VERSION ""

NS_ :

BS_:

BU_: TesterTool ECU0

BO_ 849 IPDUM_Mul0Tx: 8 ECU0
 SG_ IpduM_MulMsg0Tx_Sig10_Static : 56|8@1+ (1,0) [0|255] ""  TesterTool
 SG_ IpduM_MulMsg0Tx_Sig9_Static : 48|8@1+ (1,0) [0|255] ""  TesterTool
 SG_ IpduM_MulMsg0Tx_Sig8_Static : 40|8@1+ (1,0) [0|255] ""  TesterTool
 SG_ IpduM_MulMsg0Tx_Sig7_Static : 32|8@1+ (1,0) [0|255] ""  TesterTool
 SG_ IpduM_MulMsg0Tx_Sig6_Static : 24|8@1+ (1,0) [0|255] ""  TesterTool
 SG_ IpduM_MulMsg0Tx_Sig5_Static : 16|8@1+ (1,0) [0|255] ""  TesterTool
 SG_ IpduM_MulMsg0Tx_Sig4_Dyn m1 : 14|2@1+ (1,0) [0|3] ""  TesterTool
 SG_ IpduM_MulMsg0Tx_Sig3_Dyn m1 : 8|6@1+ (1,0) [0|63] ""  TesterTool
 SG_ IpduM_MulMsg0Tx_Sig2_Dyn m0 : 11|5@1+ (1,0) [0|31] ""  TesterTool
 SG_ IpduM_MulMsg0Tx_Sig1_Dyn m0 : 8|3@1+ (1,0) [0|7] ""  TesterTool
 SG_ IpduM_MulMsg0Tx_Sig0_Selector M : 6|2@1+ (1,0) [0|3] ""  TesterTool

BO_ 768 IPDUM_Mul0Rx: 8 TesterTool
 SG_ IpduM_MulMsg0Rx_Sig9_Static : 56|8@1+ (1,0) [0|255] ""  ECU0
 SG_ IpduM_MulMsg0Rx_Sig8_Static : 48|8@1+ (1,0) [0|255] ""  ECU0
 SG_ IpduM_MulMsg0Rx_Sig7_Static : 40|8@1+ (1,0) [0|255] ""  ECU0
 SG_ IpduM_MulMsg0Rx_Sig6_Static : 32|8@1+ (1,0) [0|255] ""  ECU0
 SG_ IpduM_MulMsg0Rx_Sig5_Static : 24|8@1+ (1,0) [0|255] ""  ECU0
 SG_ IpduM_MulMsg0Rx_Sig4_Static : 16|8@1+ (1,0) [0|255] ""  ECU0
 SG_ IpduM_MulMsg0Rx_Sig3_Dyn m1 : 12|4@1+ (1,0) [0|15] ""  ECU0
 SG_ IpduM_MulMsg0Rx_Sig2_Dyn m1 : 8|4@1+ (1,0) [0|15] ""  ECU0
 SG_ IpduM_MulMsg0Rx_Sig1_Dyn m0 : 8|8@1+ (1,0) [0|255] ""  ECU0
 SG_ IpduM_MulMsg0Rx_Sig0_Seclector M : 6|2@1+ (1,0) [0|3] ""  ECU0

BO_ 1878 CANTP_UdsFuncResp: 8 ECU0
 SG_ CanTp_UdsFuncResp_SigAll : 0|64@1+ (1,0) [0|1.84467440737096E+019] ""  TesterTool

BO_ 2015 CANTP_UdsFuncReq: 8 TesterTool
 SG_ CanTp_UdsFuncReq_SigAll : 0|64@1+ (1,0) [0|1.84467440737096E+019] ""  ECU0

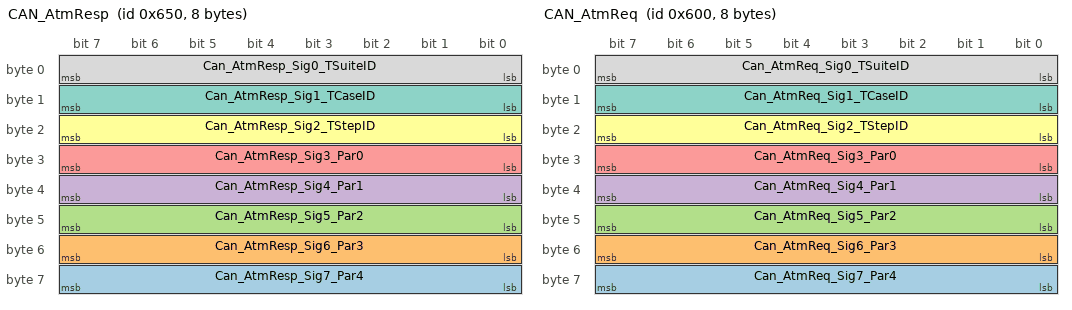
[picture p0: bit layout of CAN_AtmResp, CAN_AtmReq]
BO_ 1616 CAN_AtmResp: 8 ECU0
 SG_ Can_AtmResp_Sig7_Par4 : 56|8@1+ (1,0) [0|255] ""  TesterTool
 SG_ Can_AtmResp_Sig6_Par3 : 48|8@1+ (1,0) [0|255] ""  TesterTool
 SG_ Can_AtmResp_Sig5_Par2 : 40|8@1+ (1,0) [0|255] ""  TesterTool
 SG_ Can_AtmResp_Sig4_Par1 : 32|8@1+ (1,0) [0|255] ""  TesterTool
 SG_ Can_AtmResp_Sig3_Par0 : 24|8@1+ (1,0) [0|255] ""  TesterTool
 SG_ Can_AtmResp_Sig2_TStepID : 16|8@1+ (1,0) [0|255] ""  TesterTool
 SG_ Can_AtmResp_Sig1_TCaseID : 8|8@1+ (1,0) [0|255] ""  TesterTool
 SG_ Can_AtmResp_Sig0_TSuiteID : 0|8@1+ (1,0) [0|255] ""  TesterTool

BO_ 1536 CAN_AtmReq: 8 TesterTool
 SG_ Can_AtmReq_Sig7_Par4 : 56|8@1+ (1,0) [0|255] ""  ECU0
 SG_ Can_AtmReq_Sig6_Par3 : 48|8@1+ (1,0) [0|255] ""  ECU0
 SG_ Can_AtmReq_Sig5_Par2 : 40|8@1+ (1,0) [0|255] ""  ECU0
 SG_ Can_AtmReq_Sig4_Par1 : 32|8@1+ (1,0) [0|255] ""  ECU0
 SG_ Can_AtmReq_Sig3_Par0 : 24|8@1+ (1,0) [0|255] ""  ECU0
 SG_ Can_AtmReq_Sig2_TStepID : 16|8@1+ (1,0) [0|255] ""  ECU0
 SG_ Can_AtmReq_Sig1_TCaseID : 8|8@1+ (1,0) [0|255] ""  ECU0
 SG_ Can_AtmReq_Sig0_TSuiteID : 0|8@1+ (1,0) [0|255] ""  ECU0

BA_DEF_ SG_  "GenSigSendType" ENUM  "Cyclic","OnWrite","OnWriteWithRepetition","OnChange","OnChangeWithRepetition","IfActive","IfActiveWithRepetition","NoSigSendType";
BA_DEF_ SG_  "GenSigEnvVarType" ENUM  "int","float","undef";
BA_DEF_ SG_  "SignalCategory" HEX 10 15;
BA_DEF_ SG_  "GwSigMissingSourceType" ENUM  "Undef","OldValue","DefaultValue","InitialValue";
BA_DEF_ SG_  "GwSigLatencyTime" INT 0 65535;
BA_DEF_ BO_  "GenMsgCycleTimeFast" INT 0 500;
BA_DEF_ BO_  "GenMsgCycleTime" INT 0 2000;
BA_DEF_ BO_  "GenMsgDelayTime" INT 0 20;
BA_DEF_ BO_  "GenMsgNrOfRepetition" INT 0 3;
BA_DEF_ BO_  "GenMsgSendType" ENUM  "Cyclic","not_used","not_used","not_used","not_used","not_used","not_used","not_used","NoMsgSendType";
BA_DEF_ BO_  "GenMsgILSupport" ENUM  "No","Yes";
BA_DEF_ BU_  "ILUsed" ENUM  "No","Yes";
BA_DEF_ BU_  "NmCAN" INT 1 2;
BA_DEF_ BU_  "NmNode" ENUM  "No","Yes";
BA_DEF_ BU_  "GenNodSleepTime" INT 1375 1650;
BA_DEF_ BU_  "NodeLayerModules" STRING ;
BA_DEF_  "SyncJumpWidthMax" INT 1 8;
BA_DEF_  "SyncJumpWidthMin" INT 1 4;
BA_DEF_  "SamplePointMax" INT 50 85;
BA_DEF_  "SamplePointMin" INT 55 85;
BA_DEF_  "Manufacturer" STRING ;
BA_DEF_  "NmMessageCount" INT 0 128;
BA_DEF_  "NmBaseAddress" HEX 0 2047;
BA_DEF_  "NmType" STRING ;
BA_DEF_  "GenEnvVarEndingDsp" STRING ;
BA_DEF_  "GenEnvVarEndingSnd" STRING ;
BA_DEF_  "GenEnvVarPrefix" STRING ;
BA_DEF_  "GenNWMApBusSleep" STRING ;
BA_DEF_  "GenNWMApCanNormal" STRING ;
BA_DEF_  "GenNWMApCanOff" STRING ;
BA_DEF_  "GenNWMApCanOn" STRING ;
BA_DEF_  "GenNWMApCanSleep" STRING ;
BA_DEF_  "GenNWMApCanWakeUp" STRING ;
BA_DEF_  "GenNWMGotoMode_Awake" STRING ;
BA_DEF_  "GenNWMGotoMode_BusSleep" STRING ;
BA_DEF_  "GenNWMSleepTime" INT 1375 1650;
BA_DEF_  "GenNWMTalkNM" STRING ;
BA_DEF_  "VersionDay" INT 1 31;
BA_DEF_  "VersionMonth" INT 1 12;
BA_DEF_  "VersionWeek" INT 1 53;
BA_DEF_  "Baudrate" INT 10000 2000000;
BA_DEF_  "BusType" STRING ;
BA_DEF_REL_ BU_SG_REL_  "GenSigTimeoutTime" INT 175 3500;
BA_DEF_DEF_  "GenSigSendType" "NoSigSendType";
BA_DEF_DEF_  "GenSigEnvVarType" "undef";
BA_DEF_DEF_  "SignalCategory" 12;
BA_DEF_DEF_  "GwSigMissingSourceType" "Undef";
BA_DEF_DEF_  "GwSigLatencyTime" 40;
BA_DEF_DEF_  "GenMsgCycleTimeFast" 40;
BA_DEF_DEF_  "GenMsgCycleTime" 200;
BA_DEF_DEF_  "GenMsgDelayTime" 20;
BA_DEF_DEF_  "GenMsgNrOfRepetition" 3;
BA_DEF_DEF_  "GenMsgSendType" "NoMsgSendType";
BA_DEF_DEF_  "GenMsgILSupport" "Yes";
BA_DEF_DEF_  "ILUsed" "Yes";
BA_DEF_DEF_  "NmCAN" 1;
BA_DEF_DEF_  "NmNode" "Yes";
BA_DEF_DEF_  "GenNodSleepTime" 1500;
BA_DEF_DEF_  "NodeLayerModules" "oseknm01.dll";
BA_DEF_DEF_  "SyncJumpWidthMax" 3;
BA_DEF_DEF_  "SyncJumpWidthMin" 2;
BA_DEF_DEF_  "SamplePointMax" 82;
BA_DEF_DEF_  "SamplePointMin" 75;
BA_DEF_DEF_  "Manufacturer" "HMC";
BA_DEF_DEF_  "NmMessageCount" 128;
BA_DEF_DEF_  "NmBaseAddress" 1024;
BA_DEF_DEF_  "NmType" "Vector";
BA_DEF_DEF_  "GenEnvVarEndingDsp" "Dsp_";
BA_DEF_DEF_  "GenEnvVarEndingSnd" "_";
BA_DEF_DEF_  "GenEnvVarPrefix" "Env";
BA_DEF_DEF_  "GenNWMApBusSleep" "ApplNmCanBusSleep()";
BA_DEF_DEF_  "GenNWMApCanNormal" "ApplNmCanNormal()";
BA_DEF_DEF_  "GenNWMApCanOff" "ApplCanOffline()";
BA_DEF_DEF_  "GenNWMApCanOn" "ApplCanOnline()";
BA_DEF_DEF_  "GenNWMApCanSleep" "ApplNmCanSleep()";
BA_DEF_DEF_  "GenNWMApCanWakeUp" "ApplCanWakeUp()";
BA_DEF_DEF_  "GenNWMGotoMode_Awake" "GotoMode_Awake()";
BA_DEF_DEF_  "GenNWMGotoMode_BusSleep" "GotoMode_BusSleep()";
BA_DEF_DEF_  "GenNWMSleepTime" 1500;
BA_DEF_DEF_  "GenNWMTalkNM" "TalkNM()";
BA_DEF_DEF_  "VersionDay" 1;
BA_DEF_DEF_  "VersionMonth" 1;
BA_DEF_DEF_  "VersionWeek" 1;
BA_DEF_DEF_  "Baudrate" 500000;
BA_DEF_DEF_  "BusType" "CAN";
BA_DEF_DEF_REL_ "GenSigTimeoutTime" 700;
